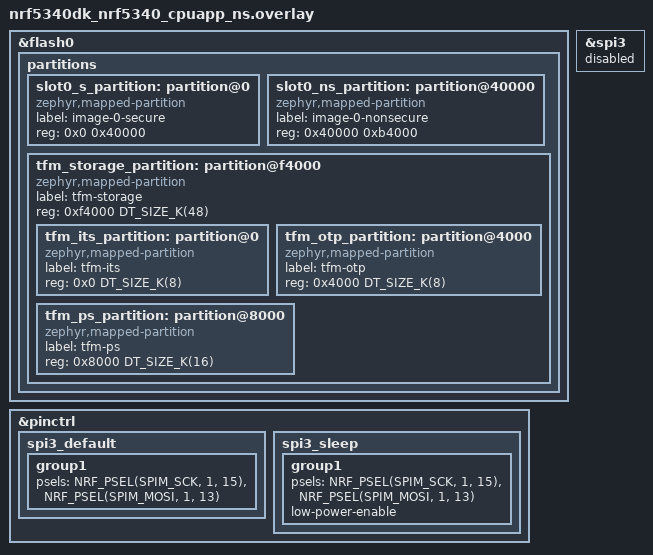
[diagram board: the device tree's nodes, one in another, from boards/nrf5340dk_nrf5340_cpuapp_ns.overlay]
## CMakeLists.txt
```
#
# Copyright (c) 2022 Nordic Semiconductor ASA
#
# SPDX-License-Identifier: LicenseRef-Nordic-5-Clause
#

cmake_minimum_required(VERSION 3.20)

find_package(Zephyr REQUIRED HINTS $ENV{ZEPHYR_BASE})

if(NOT CONFIG_BUILD_WITH_TFM)
  message(WARNING "Unsupported configuration!! CONFIG_BUILD_WITH_TFM is not enabled in this build"
                  " which is required. Either the secure only variant of the board is selected or"
                  " the CONFIG_BUILD_WITH_TFM was disabled through menuconfig. Make sure that you"
                  " build with the non-secure variant of your board (target ends with /ns) and"
                  " that you have CONFIG_BUILD_WITH_TFM enabled in your build. It is advised to"
                  " build with pristine build (append -p in the build) after you encounter this .")
endif()

if(CONFIG_SOC_SERIES_NRF53X OR CONFIG_SOC_SERIES_NRF91X)
  set(TFM_PERIPHERAL_TIMER_N  "TFM_PERIPHERAL_TIMER1")
  set(TFM_PERIPHERAL_SPIM_N   "TFM_PERIPHERAL_SPIM3")
  set(TFM_TIMER_N_IRQ         "TFM_TIMER1_IRQ")
  set(TFM_SPIM_N_IRQ          "TFM_SPIM3_IRQ")
  set(TFM_GPIOTE_N_IRQ        "TFM_GPIOTE0_IRQ")
  set(GPIOTE_MMIO             "")
elseif(CONFIG_SOC_SERIES_NRF54LX)
  set(TFM_PERIPHERAL_TIMER_N  "TFM_PERIPHERAL_TIMER10")
  set(TFM_PERIPHERAL_SPIM_N   "TFM_PERIPHERAL_SPIM30")
  set(TFM_TIMER_N_IRQ         "TFM_TIMER10_IRQ")
  set(TFM_SPIM_N_IRQ          "TFM_SPIM30_IRQ")
  set(TFM_GPIOTE_N_IRQ        "TFM_GPIOTE20_1_IRQ")
  set(GPIOTE_MMIO [[
    {
      "name": "TFM_PERIPHERAL_GPIOTE20",
      "permission": "READ-WRITE"
    },
    ]])
else()
  message(FATAL_ERROR "Board not supported.")
endif()

get_target_property(TFM_BINARY_DIR tfm TFM_BINARY_DIR)

configure_file(
  ${CMAKE_CURRENT_LIST_DIR}/secure_peripheral_partition/tfm_secure_peripheral_partition.yaml.in
  ${CMAKE_CURRENT_BINARY_DIR}/secure_peripheral_partition/tfm_secure_peripheral_partition.yaml
)

configure_file(
  ${CMAKE_CURRENT_LIST_DIR}/secure_peripheral_partition/tfm_manifest_list.yaml.in
  ${CMAKE_CURRENT_BINARY_DIR}/secure_peripheral_partition/tfm_manifest_list.yaml
)

set_property(TARGET zephyr_property_target
  APPEND PROPERTY TFM_CMAKE_OPTIONS
  -DTFM_EXTRA_MANIFEST_LIST_FILES=${CMAKE_CURRENT_BINARY_DIR}/secure_peripheral_partition/tfm_manifest_list.yaml
  -DTFM_EXTRA_PARTITION_PATHS=${CMAKE_CURRENT_LIST_DIR}/secure_peripheral_partition
)

project(tfm_secure_partition)

target_sources(app PRIVATE
  src/main.c
  src/secure_peripheral_partition.c
)

target_include_directories(app PRIVATE
  $<TARGET_PROPERTY:tfm,TFM_BINARY_DIR>/api_ns/interface/include
)

target_compile_definitions(app
    PRIVATE TFM_PARTITION_SECURE_PERIPHERAL_PARTITION
)
```

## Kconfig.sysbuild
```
#
# Copyright (c) 2026 Nordic Semiconductor
#
# SPDX-License-Identifier: LicenseRef-Nordic-5-Clause
#

config PARTITION_MANAGER
	default n if !SOC_SERIES_NRF91 && (!SOC_SERIES_NRF53 || BOARD_IS_NON_SECURE)

source "share/sysbuild/Kconfig"
```

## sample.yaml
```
sample:
  name: TF-M Secure Peripheral Sample
  description: |
    TF-M sample demonstrating use of secure peripherals in a secure partition
common:
  tags:
    - tfm
    - ci_samples_tfm
  platform_allow:
    - nrf5340dk/nrf5340/cpuapp/ns
    - nrf9151dk/nrf9151/ns
    - nrf9160dk/nrf9160/ns
    - nrf9161dk/nrf9161/ns
    - nrf54lv10dk/nrf54lv10a/cpuapp/ns
  integration_platforms:
    - nrf5340dk/nrf5340/cpuapp/ns
    - nrf9151dk/nrf9151/ns
    - nrf9160dk/nrf9160/ns
    - nrf9161dk/nrf9161/ns
    - nrf54lv10dk/nrf54lv10a/cpuapp/ns
  harness: console
  harness_config:
    type: multi_line
    regex:
      - "SPP: sending message: Success"
      - "SPP: processing signals: Success"
tests:
  sample.tfm.secure_peripheral:
    sysbuild: true
    tags:
      - tfm
      - ci_build
      - sysbuild
      - ci_samples_tfm
```

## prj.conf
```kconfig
#
# Copyright (c) 2022 Nordic Semiconductor ASA
#
# SPDX-License-Identifier: LicenseRef-Nordic-5-Clause
#

CONFIG_TFM_PROFILE_TYPE_NOT_SET=y
CONFIG_TFM_IPC=y
CONFIG_TFM_ISOLATION_LEVEL=1
CONFIG_PSA_WANT_ALG_SHA_256=y

CONFIG_TFM_SPM_LOG_LEVEL_DEBUG=y
```

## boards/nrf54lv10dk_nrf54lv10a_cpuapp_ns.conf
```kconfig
#
# Copyright (c) 2025 Nordic Semiconductor ASA
#
# SPDX-License-Identifier: LicenseRef-Nordic-5-Clause
#

# P1: 5 (SPIM_MOSI), 6 (SPIM_SCK) 13 (button0)
CONFIG_NRF_GPIO1_PIN_MASK_SECURE=0x00002060

CONFIG_NRF_TIMER10_SECURE=y
CONFIG_NRF_SPIM30_SECURE=y
CONFIG_NRF_GPIOTE20_SECURE=y
CONFIG_NRF_GPIOTE20_SECURE_CHANNELS_MASK=0x2
```

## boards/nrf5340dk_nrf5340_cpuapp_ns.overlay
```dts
/* Copyright (c) 2022 Nordic Semiconductor ASA
 *
 * SPDX-License-Identifier: LicenseRef-Nordic-5-Clause
 */

/delete-node/ &boot_partition;
/delete-node/ &slot0_partition;
/delete-node/ &slot1_partition;
/delete-node/ &storage_partition;

/delete-node/ &tfm_its_partition;
/delete-node/ &tfm_otp_partition;
/delete-node/ &tfm_ps_partition;

&flash0 {
	partitions {
		slot0_s_partition: partition@0 {
			compatible = "zephyr,mapped-partition";
			label = "image-0-secure";
			reg = <0x0 0x40000>;
		};

		slot0_ns_partition: partition@40000 {
			compatible = "zephyr,mapped-partition";
			label = "image-0-nonsecure";
			reg = <0x40000 0xb4000>;
		};

		tfm_storage_partition: partition@f4000 {
			compatible = "zephyr,mapped-partition";
			label = "tfm-storage";
			reg = <0xf4000 DT_SIZE_K(48)>;
			ranges = <0x0 0xf4000 DT_SIZE_K(48)>;
			#address-cells = <1>;
			#size-cells = <1>;

			tfm_its_partition: partition@0 {
				compatible = "zephyr,mapped-partition";
				label = "tfm-its";
				reg = <0x0 DT_SIZE_K(8)>;
			};

			tfm_otp_partition: partition@4000 {
				compatible = "zephyr,mapped-partition";
				label = "tfm-otp";
				reg = <0x4000 DT_SIZE_K(8)>;
			};

			tfm_ps_partition: partition@8000 {
				compatible = "zephyr,mapped-partition";
				label = "tfm-ps";
				reg = <0x8000 DT_SIZE_K(16)>;
			};
		};
	};
};

&pinctrl {
	spi3_default: spi3_default {
		group1 {
			psels = <NRF_PSEL(SPIM_SCK, 1, 15)>,
				<NRF_PSEL(SPIM_MOSI, 1, 13)>;
		};
	};

	spi3_sleep: spi3_sleep {
		group1 {
			psels = <NRF_PSEL(SPIM_SCK, 1, 15)>,
				<NRF_PSEL(SPIM_MOSI, 1, 13)>;
			low-power-enable;
		};
	};
};

&spi3 {
	/* Disabled in non-secure image. */
	status = "disabled";
};
```

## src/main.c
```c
/*
 * Copyright (c) 2022 Nordic Semiconductor ASA.
 *
 * SPDX-License-Identifier: LicenseRef-Nordic-5-Clause
 */

#include <zephyr/kernel.h>
#include <tfm_ns_interface.h>

#include "secure_peripheral_partition.h"

#include <hal/nrf_egu.h>

#define EGU_INT_PRIO 4
static K_SEM_DEFINE(spp_process_sem, 0, 1);

#if defined(CONFIG_SOC_SERIES_NRF53X) || defined(CONFIG_SOC_SERIES_NRF91X)
#define NRF_EGU_N  NRF_EGU0
#define EGU_N_IRQn EGU0_IRQn

#elif defined(CONFIG_SOC_SERIES_NRF54LX)
#define NRF_EGU_N NRF_EGU10
#define EGU_N_IRQn EGU10_IRQn
#endif

static struct k_work process_work;
static struct k_work_delayable send_work;

static void egu_handler(const void *context)
{
	nrf_egu_event_clear(NRF_EGU_N, NRF_EGU_EVENT_TRIGGERED0);

	k_work_submit(&process_work);
}

static void process(struct k_work *work)
{
	psa_status_t status;

	printk("SPP: processing signals: ");
	status = spp_process();
	if (status == PSA_SUCCESS) {
		printk("Success\n");
	} else {
		printk("ERROR: spp_process status: %d\n", status);
	}
}

static void send(struct k_work *work)
{
	psa_status_t status;

	printk("SPP: sending message: ");
	status = spp_send();
	if (status == PSA_SUCCESS) {
		printk("Success\n");
	} else {
		printk("ERROR: spp_send status: %d\n", status);
	}

	k_work_schedule(&send_work, K_SECONDS(20));
}

int main(void)
{
	IRQ_CONNECT(EGU_N_IRQn, EGU_INT_PRIO, egu_handler, NULL, 0);
	nrf_egu_int_enable(NRF_EGU_N, NRF_EGU_INT_TRIGGERED0);
	NVIC_EnableIRQ(EGU_N_IRQn);
	k_work_init(&process_work, process);
	k_work_init_delayable(&send_work, send);
	k_work_schedule(&send_work, K_NO_WAIT);
	return 0;
}
```

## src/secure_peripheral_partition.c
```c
/*
 * Copyright (c) 2022 Nordic Semiconductor ASA.
 *
 * SPDX-License-Identifier: LicenseRef-Nordic-5-Clause
 */

#include <tfm_ns_interface.h>

#include "secure_peripheral_partition.h"

#include "psa/client.h"
#include "psa_manifest/sid.h"
#include <zephyr/kernel.h>

psa_status_t spp_process(void)
{
	psa_status_t status;
	psa_handle_t handle = TFM_SPP_PROCESS_HANDLE;
	status = psa_call(handle, PSA_IPC_CALL, NULL, 0, NULL, 0);

	return status;
}

psa_status_t spp_send(void)
{
	psa_status_t status;
	psa_handle_t handle = TFM_SPP_SEND_HANDLE;
	status = psa_call(handle, PSA_IPC_CALL, NULL, 0, NULL, 0);

	return status;
}
```
